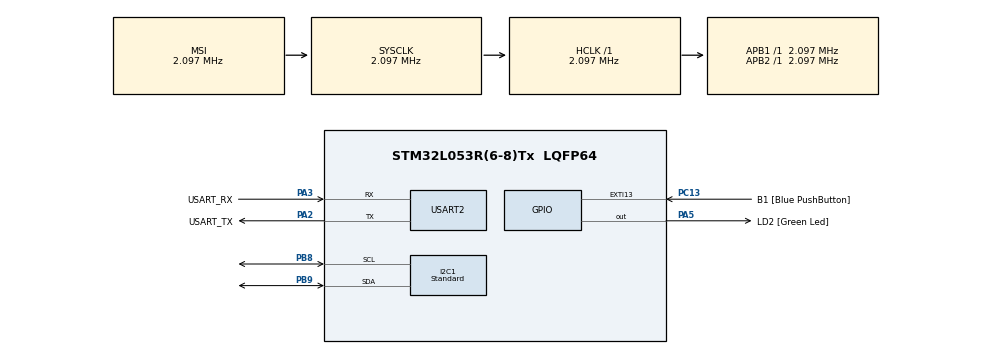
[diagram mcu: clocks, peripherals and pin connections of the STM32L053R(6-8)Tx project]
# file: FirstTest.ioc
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I2C1.I2C_Speed_Mode=I2C_Standard
Mcu.Family=STM32L0
Mcu.Name=STM32L053R(6-8)Tx
Mcu.Package=LQFP64
NVIC.RTC_IRQn=true\:0\:0\:false\:false\:true\:true\:true
PA0.Mode=SYS_WakeUp0
PA0.Signal=SYS_WKUP1
PA13.GPIO_Label=TMS
PA13.Mode=Serial_Wire
PA13.Signal=SYS_SWDIO
PA14.GPIO_Label=TCK
PA14.Mode=Serial_Wire
PA14.Signal=SYS_SWCLK
PA2.GPIO_Label=USART_TX
PA2.Mode=Asynchronous
PA2.Signal=USART2_TX
PA3.GPIO_Label=USART_RX
PA3.Mode=Asynchronous
PA3.Signal=USART2_RX
PA5.GPIO_Label=LD2 [Green Led]
PA5.Signal=GPIO_Output
PB8.Mode=I2C
PB8.Signal=I2C1_SCL
PB9.Mode=I2C
PB9.Signal=I2C1_SDA
PC13.GPIO_Label=B1 [Blue PushButton]
PC13.GPIO_ModeDefaultEXTI=GPIO_MODE_IT_FALLING
PC13.Signal=GPXTI13
PC14-OSC32_IN.Mode=LSE-External-Oscillator
PC14-OSC32_IN.Signal=RCC_OSC32_IN
PC15-OSC32_OUT.Mode=LSE-External-Oscillator
PC15-OSC32_OUT.Signal=RCC_OSC32_OUT
PH0-OSC_IN.Signal=RCC_OSC_IN
PH1-OSC_OUT.Signal=RCC_OSC_OUT
ProjectManager.HeapSize=0x200
ProjectManager.StackSize=0x400
ProjectManager.TargetToolchain=STM32CubeIDE
RCC.AHBFreq_Value=2097000
RCC.APB1Freq_Value=2097000
RCC.APB1TimFreq_Value=2097000
RCC.APB2Freq_Value=2097000
RCC.APB2TimFreq_Value=2097000
RCC.HCLKFreq_Value=2097000
RCC.HSE_VALUE=8000000
RCC.HSI16_VALUE=16000000
RCC.HSI48_VALUE=48000000
RCC.HSI_VALUE=16000000
RCC.MSI_VALUE=2097000
RCC.RTCClockSelectionVirtual=RCC_RTCCLKSOURCE_LSE
RCC.SYSCLKFreq_VALUE=2097000
RCC.VCOOutputFreq_Value=48000000
RTC.Alarm-Alarm\ A=RTC_ALARM_A
RTC.AlarmMaskDateWeekDay-Alarm\ A=RTC_ALARMMASK_DATEWEEKDAY
RTC.AlarmMaskHours-Alarm\ A=RTC_ALARMMASK_HOURS
USART2.VirtualMode-Asynchronous=VM_ASYNC
VP_RTC_VS_RTC_Activate.Mode=RTC_Enabled
VP_RTC_VS_RTC_Alarm_A_Intern.Mode=Alarm A
VP_RTC_VS_RTC_Calendar.Mode=RTC_Calendar
board=NUCLEO-L053R8

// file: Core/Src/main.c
/* USER CODE BEGIN Header */
/**
  ******************************************************************************
  * @file           : main.c
  * @brief          : Main program body
  ******************************************************************************
  * @attention
  *
  * <h2><center>&copy; Copyright (c) 2020 STMicroelectronics.
  * All rights reserved.</center></h2>
  *
  * This software component is licensed by ST under BSD 3-Clause license,
  * the "License"; You may not use this file except in compliance with the
  * License. You may obtain a copy of the License at:
  *                        opensource.org/licenses/BSD-3-Clause
  *
  ******************************************************************************
  */
/* USER CODE END Header */

#include "main.h"

/* USER CODE BEGIN Includes */
#include "usermain.hpp"

/* USER CODE END Includes */

I2C_HandleTypeDef hi2c1;

RTC_HandleTypeDef hrtc;

UART_HandleTypeDef huart2;

void SystemClock_Config(void);
static void MX_GPIO_Init(void);
static void MX_USART2_UART_Init(void);
void MX_RTC_Init(void);
static void MX_I2C1_Init(void);

/* USER CODE BEGIN 0 */
uint32_t time = 0;

void HAL_RTC_AlarmAEventCallback(RTC_HandleTypeDef *hrtc)
{
	uint32_t i = HAL_RTCEx_BKUPRead(hrtc, 0);
	i++;
	Interrupt_counter = i<<16;
	HAL_RTCEx_BKUPWrite(hrtc, 0, i);
}
/* USER CODE END 0 */

int main(void)
{

  /* MCU Configuration--------------------------------------------------------*/

  /* Reset of all peripherals, Initializes the Flash interface and the Systick. */
  HAL_Init();

  /* Configure the system clock */
  SystemClock_Config();

  /* Initialize all configured peripherals */
  MX_GPIO_Init();
  MX_USART2_UART_Init();
  MX_RTC_Init();
  MX_I2C1_Init();

  /* Infinite loop */
  /* USER CODE BEGIN WHILE */
  usermain_init();

  while (1)
  {
	  HAL_GPIO_TogglePin(LD2_GPIO_Port, LD2_Pin);
	  //HAL_Delay(1000);
	  //a++;
	  //HAL_RTC_WaitForSynchro(&hrtc);
	  //HAL_RTC_GetTime(&hrtc, &time_cs, RTC_FORMAT_BIN);
	  //HAL_RTC_GetDate(&hrtc, &date_cs, RTC_FORMAT_BIN);
	  //time = time_cs.Hours*10000+time_cs.Minutes*100+time_cs.Seconds;
	  usermain_loop();
    /* USER CODE END WHILE */

  }
}

void SystemClock_Config(void)
{
  RCC_OscInitTypeDef RCC_OscInitStruct = {0};
  RCC_ClkInitTypeDef RCC_ClkInitStruct = {0};
  RCC_PeriphCLKInitTypeDef PeriphClkInit = {0};

  /** Configure the main internal regulator output voltage
  */
  __HAL_PWR_VOLTAGESCALING_CONFIG(PWR_REGULATOR_VOLTAGE_SCALE1);
  /** Configure LSE Drive Capability
  */
  HAL_PWR_EnableBkUpAccess();
  __HAL_RCC_LSEDRIVE_CONFIG(RCC_LSEDRIVE_LOW);
  /** Initializes the CPU, AHB and APB busses clocks
  */
  RCC_OscInitStruct.OscillatorType = RCC_OSCILLATORTYPE_LSE|RCC_OSCILLATORTYPE_MSI;
  RCC_OscInitStruct.LSEState = RCC_LSE_ON;
  RCC_OscInitStruct.MSIState = RCC_MSI_ON;
  RCC_OscInitStruct.MSICalibrationValue = 0;
  RCC_OscInitStruct.MSIClockRange = RCC_MSIRANGE_5;
  RCC_OscInitStruct.PLL.PLLState = RCC_PLL_NONE;
  if (HAL_RCC_OscConfig(&RCC_OscInitStruct) != HAL_OK)
  {
    Error_Handler();
  }
  /** Initializes the CPU, AHB and APB busses clocks
  */
  RCC_ClkInitStruct.ClockType = RCC_CLOCKTYPE_HCLK|RCC_CLOCKTYPE_SYSCLK
                              |RCC_CLOCKTYPE_PCLK1|RCC_CLOCKTYPE_PCLK2;
  RCC_ClkInitStruct.SYSCLKSource = RCC_SYSCLKSOURCE_MSI;
  RCC_ClkInitStruct.AHBCLKDivider = RCC_SYSCLK_DIV1;
  RCC_ClkInitStruct.APB1CLKDivider = RCC_HCLK_DIV1;
  RCC_ClkInitStruct.APB2CLKDivider = RCC_HCLK_DIV1;

  if (HAL_RCC_ClockConfig(&RCC_ClkInitStruct, FLASH_LATENCY_0) != HAL_OK)
  {
    Error_Handler();
  }
  PeriphClkInit.PeriphClockSelection = RCC_PERIPHCLK_USART2|RCC_PERIPHCLK_I2C1
                              |RCC_PERIPHCLK_RTC;
  PeriphClkInit.Usart2ClockSelection = RCC_USART2CLKSOURCE_PCLK1;
  PeriphClkInit.I2c1ClockSelection = RCC_I2C1CLKSOURCE_PCLK1;
  PeriphClkInit.RTCClockSelection = RCC_RTCCLKSOURCE_LSE;
  if (HAL_RCCEx_PeriphCLKConfig(&PeriphClkInit) != HAL_OK)
  {
    Error_Handler();
  }
}

static void MX_I2C1_Init(void)
{

  hi2c1.Instance = I2C1;
  hi2c1.Init.Timing = 0x00000708;
  hi2c1.Init.OwnAddress1 = 0;
  hi2c1.Init.AddressingMode = I2C_ADDRESSINGMODE_7BIT;
  hi2c1.Init.DualAddressMode = I2C_DUALADDRESS_DISABLE;
  hi2c1.Init.OwnAddress2 = 0;
  hi2c1.Init.OwnAddress2Masks = I2C_OA2_NOMASK;
  hi2c1.Init.GeneralCallMode = I2C_GENERALCALL_DISABLE;
  hi2c1.Init.NoStretchMode = I2C_NOSTRETCH_DISABLE;
  if (HAL_I2C_Init(&hi2c1) != HAL_OK)
  {
    Error_Handler();
  }
  /** Configure Analogue filter
  */
  if (HAL_I2CEx_ConfigAnalogFilter(&hi2c1, I2C_ANALOGFILTER_ENABLE) != HAL_OK)
  {
    Error_Handler();
  }
  /** Configure Digital filter
  */
  if (HAL_I2CEx_ConfigDigitalFilter(&hi2c1, 0) != HAL_OK)
  {
    Error_Handler();
  }

}

void MX_RTC_Init(void)
{

  RTC_TimeTypeDef sTime = {0};
  RTC_DateTypeDef sDate = {0};
  RTC_AlarmTypeDef sAlarm = {0};

  /** Initialize RTC Only
  */
  hrtc.Instance = RTC;
  hrtc.Init.HourFormat = RTC_HOURFORMAT_24;
  hrtc.Init.AsynchPrediv = 127;
  hrtc.Init.SynchPrediv = 255;
  hrtc.Init.OutPut = RTC_OUTPUT_DISABLE;
  hrtc.Init.OutPutRemap = RTC_OUTPUT_REMAP_NONE;
  hrtc.Init.OutPutPolarity = RTC_OUTPUT_POLARITY_HIGH;
  hrtc.Init.OutPutType = RTC_OUTPUT_TYPE_OPENDRAIN;
  if (HAL_RTC_Init(&hrtc) != HAL_OK)
  {
    Error_Handler();
  }

  /* USER CODE BEGIN Check_RTC_BKUP */
	if(HAL_RTCEx_BKUPRead(&hrtc, 0) != 0)
	{
		return;// Only initialize RTC
	}

	HAL_RTCEx_BKUPWrite(&hrtc, 0, 1);//Set BackupRegister 1 so RTC wont be initialized again
  /* USER CODE END Check_RTC_BKUP */

  /** Initialize RTC and set the Time and Date
  */
  sTime.Hours = 0x0;
  sTime.Minutes = 0x0;
  sTime.Seconds = 0x0;
  sTime.DayLightSaving = RTC_DAYLIGHTSAVING_NONE;
  sTime.StoreOperation = RTC_STOREOPERATION_RESET;
  if (HAL_RTC_SetTime(&hrtc, &sTime, RTC_FORMAT_BCD) != HAL_OK)
  {
    Error_Handler();
  }
  sDate.WeekDay = RTC_WEEKDAY_MONDAY;
  sDate.Month = RTC_MONTH_JANUARY;
  sDate.Date = 0x1;
  sDate.Year = 0x0;

  if (HAL_RTC_SetDate(&hrtc, &sDate, RTC_FORMAT_BCD) != HAL_OK)
  {
    Error_Handler();
  }
  /** Enable the Alarm A
  */
  sAlarm.AlarmTime.Hours = 0x0;
  sAlarm.AlarmTime.Minutes = 0x0;
  sAlarm.AlarmTime.Seconds = 0x0;
  sAlarm.AlarmTime.SubSeconds = 0x0;
  sAlarm.AlarmTime.DayLightSaving = RTC_DAYLIGHTSAVING_NONE;
  sAlarm.AlarmTime.StoreOperation = RTC_STOREOPERATION_RESET;
  sAlarm.AlarmMask = RTC_ALARMMASK_DATEWEEKDAY|RTC_ALARMMASK_HOURS;
  sAlarm.AlarmSubSecondMask = RTC_ALARMSUBSECONDMASK_ALL;
  sAlarm.AlarmDateWeekDaySel = RTC_ALARMDATEWEEKDAYSEL_DATE;
  sAlarm.AlarmDateWeekDay = 0x1;
  sAlarm.Alarm = RTC_ALARM_A;
  if (HAL_RTC_SetAlarm_IT(&hrtc, &sAlarm, RTC_FORMAT_BCD) != HAL_OK)
  {
    Error_Handler();
  }

}

static void MX_USART2_UART_Init(void)
{

  huart2.Instance = USART2;
  huart2.Init.BaudRate = 115200;
  huart2.Init.WordLength = UART_WORDLENGTH_8B;
  huart2.Init.StopBits = UART_STOPBITS_1;
  huart2.Init.Parity = UART_PARITY_NONE;
  huart2.Init.Mode = UART_MODE_TX_RX;
  huart2.Init.HwFlowCtl = UART_HWCONTROL_NONE;
  huart2.Init.OverSampling = UART_OVERSAMPLING_16;
  huart2.Init.OneBitSampling = UART_ONE_BIT_SAMPLE_DISABLE;
  huart2.AdvancedInit.AdvFeatureInit = UART_ADVFEATURE_NO_INIT;
  if (HAL_UART_Init(&huart2) != HAL_OK)
  {
    Error_Handler();
  }

}

static void MX_GPIO_Init(void)
{
  GPIO_InitTypeDef GPIO_InitStruct = {0};

  /* GPIO Ports Clock Enable */
  __HAL_RCC_GPIOC_CLK_ENABLE();
  __HAL_RCC_GPIOH_CLK_ENABLE();
  __HAL_RCC_GPIOA_CLK_ENABLE();
  __HAL_RCC_GPIOB_CLK_ENABLE();

  /*Configure GPIO pin Output Level */
  HAL_GPIO_WritePin(LD2_GPIO_Port, LD2_Pin, GPIO_PIN_RESET);

  /*Configure GPIO pin : B1_Pin */
  GPIO_InitStruct.Pin = B1_Pin;
  GPIO_InitStruct.Mode = GPIO_MODE_IT_FALLING;
  GPIO_InitStruct.Pull = GPIO_NOPULL;
  HAL_GPIO_Init(B1_GPIO_Port, &GPIO_InitStruct);

  /*Configure GPIO pin : LD2_Pin */
  GPIO_InitStruct.Pin = LD2_Pin;
  GPIO_InitStruct.Mode = GPIO_MODE_OUTPUT_PP;
  GPIO_InitStruct.Pull = GPIO_NOPULL;
  GPIO_InitStruct.Speed = GPIO_SPEED_FREQ_LOW;
  HAL_GPIO_Init(LD2_GPIO_Port, &GPIO_InitStruct);

}

void Error_Handler(void)
{
}

/************************ (C) COPYRIGHT STMicroelectronics *****END OF FILE****/
